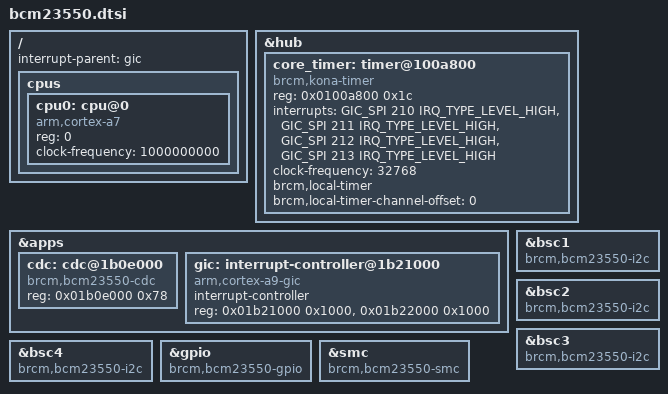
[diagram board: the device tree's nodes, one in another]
// SPDX-License-Identifier: BSD-3-Clause
/*
 * Device tree for the BCM23550 SoC.
 *
 * Copyright (C) 2016 Broadcom
 */

#include "bcm2166x-common.dtsi"

/ {
	interrupt-parent = <&gic>;

	cpus {
		#address-cells = <1>;
		#size-cells = <0>;

		cpu0: cpu@0 {
			device_type = "cpu";
			compatible = "arm,cortex-a7";
			reg = <0>;
			clock-frequency = <1000000000>;
		};

		/*
		cpu1: cpu@1 {
			device_type = "cpu";
			compatible = "arm,cortex-a7";
			enable-method = "brcm,bcm23550";
			secondary-boot-reg = <0x35004178>;
			reg = <1>;
			clock-frequency = <1000000000>;
		};

		cpu2: cpu@2 {
			device_type = "cpu";
			compatible = "arm,cortex-a7";
			enable-method = "brcm,bcm23550";
			secondary-boot-reg = <0x35004178>;
			reg = <2>;
			clock-frequency = <1000000000>;
		};

		cpu3: cpu@3 {
			device_type = "cpu";
			compatible = "arm,cortex-a7";
			enable-method = "brcm,bcm23550";
			secondary-boot-reg = <0x35004178>;
			reg = <3>;
			clock-frequency = <1000000000>;
		};
		*/
	};

	/*arch_timer: timer {
		compatible = "arm,armv7-timer";
		interrupts = <GIC_PPI 13
			(GIC_CPU_MASK_SIMPLE(4) | IRQ_TYPE_LEVEL_LOW)>,
			     <GIC_PPI 14
			(GIC_CPU_MASK_SIMPLE(4) | IRQ_TYPE_LEVEL_LOW)>,
			     <GIC_PPI 11
			(GIC_CPU_MASK_SIMPLE(4) | IRQ_TYPE_LEVEL_LOW)>,
			     <GIC_PPI 10
			(GIC_CPU_MASK_SIMPLE(4) | IRQ_TYPE_LEVEL_LOW)>;
		arm,no-tick-in-suspend;
	};*/
};

&hub {
		core_timer: timer@100a800 {
			compatible = "brcm,kona-timer";
			reg = <0x0100a800 0x1c>;
			interrupts = <GIC_SPI 210 IRQ_TYPE_LEVEL_HIGH>,
						<GIC_SPI 211 IRQ_TYPE_LEVEL_HIGH>,
						<GIC_SPI 212 IRQ_TYPE_LEVEL_HIGH>,
						<GIC_SPI 213 IRQ_TYPE_LEVEL_HIGH>;
			clock-frequency = <32768>;
			brcm,local-timer;
			brcm,local-timer-channel-offset = <0>;
		};
};

&apps {
		cdc: cdc@1b0e000 {
			compatible = "brcm,bcm23550-cdc";
			reg = <0x01b0e000 0x78>;
		};

		gic: interrupt-controller@1b21000 {
			compatible = "arm,cortex-a9-gic";
			#interrupt-cells = <3>;
			#address-cells = <0>;
			interrupt-controller;
			reg = <0x01b21000 0x1000>,
			      <0x01b22000 0x1000>;
		};
};

&bsc1 {
	compatible = "brcm,bcm23550-i2c", "brcm,kona-i2c";
};

&bsc2 {
	compatible = "brcm,bcm23550-i2c", "brcm,kona-i2c";
};

&bsc3 {
	compatible = "brcm,bcm23550-i2c", "brcm,kona-i2c";
};

&bsc4 {
	compatible = "brcm,bcm23550-i2c", "brcm,kona-i2c";
};

&gpio {
	compatible = "brcm,bcm23550-gpio", "brcm,kona-gpio";
};

&smc {
	compatible = "brcm,bcm23550-smc", "brcm,kona-smc";
};
